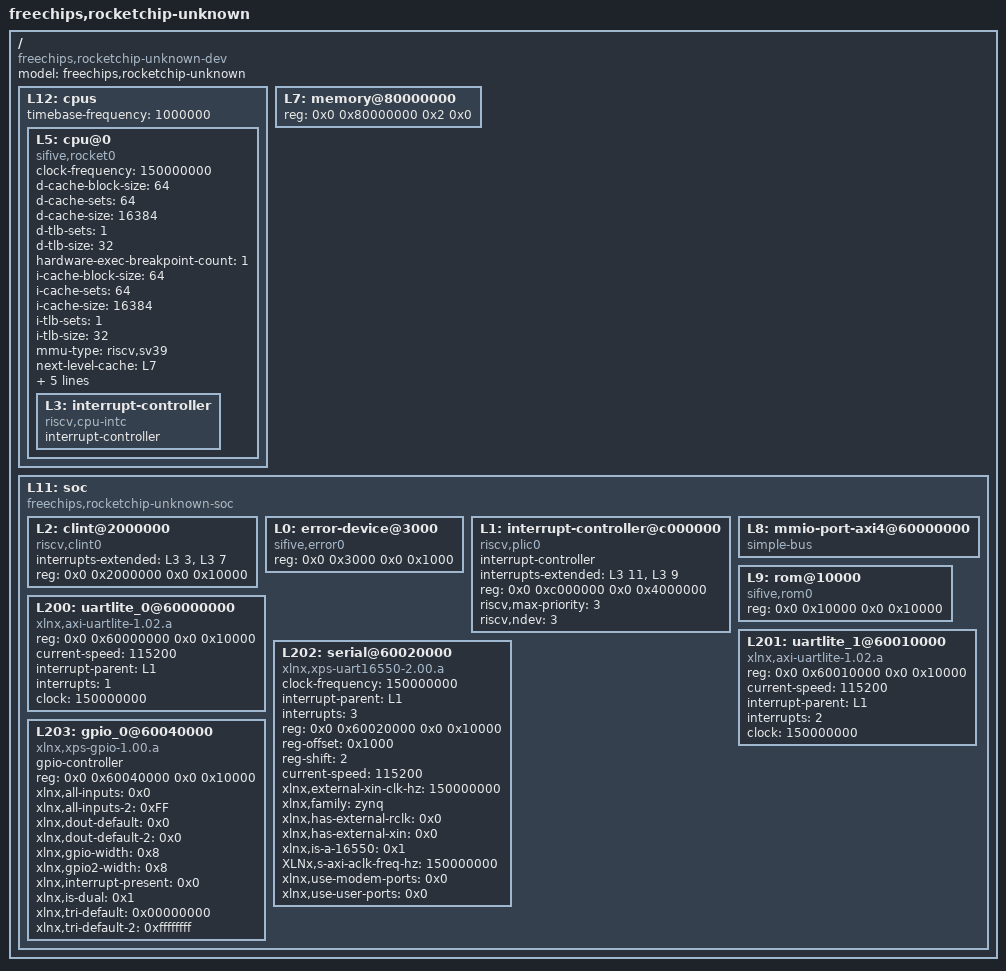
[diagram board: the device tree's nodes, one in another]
/dts-v1/;

/ {
	#address-cells = <2>;
	#size-cells = <2>;
	compatible = "freechips,rocketchip-unknown-dev";
	model = "freechips,rocketchip-unknown";
	L12: cpus {
		#address-cells = <1>;
		#size-cells = <0>;
        timebase-frequency = <1000000>;
		L5: cpu@0 {
			clock-frequency = <150000000>;
			compatible = "sifive,rocket0", "riscv";
			d-cache-block-size = <64>;
			d-cache-sets = <64>;
			d-cache-size = <16384>;
			d-tlb-sets = <1>;
			d-tlb-size = <32>;
			device_type = "cpu";
			hardware-exec-breakpoint-count = <1>;
			i-cache-block-size = <64>;
			i-cache-sets = <64>;
			i-cache-size = <16384>;
			i-tlb-sets = <1>;
			i-tlb-size = <32>;
			mmu-type = "riscv,sv39";
			next-level-cache = <&L7>;
			reg = <0x0>;
			riscv,isa = "rv64imafdc";
			riscv,pmpregions = <8>;
			status = "okay";
			timebase-frequency = <1000000>;
			tlb-split;
			L3: interrupt-controller {
				#interrupt-cells = <1>;
				compatible = "riscv,cpu-intc";
				interrupt-controller;
			};
		};
	};
	L7: memory@80000000 {
		device_type = "memory";
		reg = <0x0 0x80000000 0x2 0x0>;
	};
	L11: soc {
		#address-cells = <2>;
		#size-cells = <2>;
		compatible = "freechips,rocketchip-unknown-soc", "simple-bus";
		ranges;
		L2: clint@2000000 {
			compatible = "riscv,clint0";
			interrupts-extended = <&L3 3 &L3 7>;
			reg = <0x0 0x2000000 0x0 0x10000>;
			reg-names = "control";
		};
		L0: error-device@3000 {
			compatible = "sifive,error0";
			reg = <0x0 0x3000 0x0 0x1000>;
		};
		L1: interrupt-controller@c000000 {
			#interrupt-cells = <1>;
			compatible = "riscv,plic0";
			interrupt-controller;
			interrupts-extended = <&L3 11 &L3 9>;
			reg = <0x0 0xc000000 0x0 0x4000000>;
			reg-names = "control";
			riscv,max-priority = <3>;
			riscv,ndev = <3>;
		};
		L8: mmio-port-axi4@60000000 {
			#address-cells = <1>;
			#size-cells = <1>;
			compatible = "simple-bus";
			ranges = <0x60000000 0x0 0x60000000 0x20000000>;
		};
		L9: rom@10000 {
			compatible = "sifive,rom0";
			reg = <0x0 0x10000 0x0 0x10000>;
			reg-names = "mem";
		};
        L200: uartlite_0@60000000 {
            compatible = "xlnx,axi-uartlite-1.02.a", "xlnx,xps-uartlite-1.00.a";
            reg = <0x0 0x60000000 0x0 0x10000>;
            current-speed = <115200>;
            device_type = "serial";
            interrupt-parent = <&L1>;
            interrupts = <1>;
            clock = <150000000>;
        };
        L201: uartlite_1@60010000 {
            compatible = "xlnx,axi-uartlite-1.02.a", "xlnx,xps-uartlite-1.00.a";
            reg = <0x0 0x60010000 0x0 0x10000>;
            current-speed = <115200>;
            device_type = "serial";
            interrupt-parent = <&L1>;
            interrupts = <2>;
            clock = <150000000>;
        };
        L202: serial@60020000 {
            clock-frequency = <150000000>;
            compatible = "xlnx,xps-uart16550-2.00.a", "ns16550a";
            device_type = "serial";
            interrupt-parent = <&L1>;
            interrupts = <3>;
            reg = <0x0 0x60020000 0x0 0x10000>;
            reg-offset = <0x1000>;
            reg-shift = <2>;
            current-speed = <115200>;
            xlnx,external-xin-clk-hz = <150000000>;
            xlnx,family = "zynq";
            xlnx,has-external-rclk = <0x0>;
            xlnx,has-external-xin = <0x0>;
            xlnx,is-a-16550 = <0x1>;
            XLNx,s-axi-aclk-freq-hz = <150000000>;
            xlnx,use-modem-ports = <0x0>;
            xlnx,use-user-ports = <0x0>;
        };
        L203: gpio_0@60040000 {
            #gpio-cells = <2>;
            compatible = "xlnx,xps-gpio-1.00.a";
            gpio-controller;
            reg = <0x0 0x60040000 0x0 0x10000>;
            xlnx,all-inputs = <0x0>;
            xlnx,all-inputs-2 = <0xFF>;
            xlnx,dout-default = <0x0>;
            xlnx,dout-default-2 = <0x0>;
            xlnx,gpio-width = <0x8>;
            xlnx,gpio2-width = <0x8>;
            xlnx,interrupt-present = <0x0>;
            xlnx,is-dual = <0x1>;
            xlnx,tri-default = <0x00000000>;
            xlnx,tri-default-2 = <0xffffffff>;
        };
	};
};
